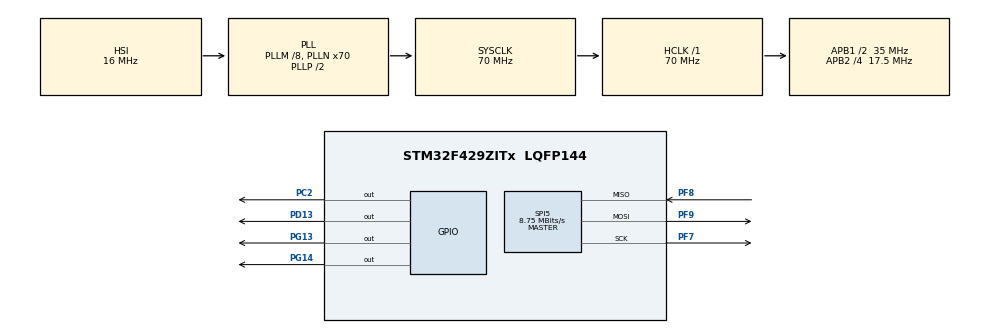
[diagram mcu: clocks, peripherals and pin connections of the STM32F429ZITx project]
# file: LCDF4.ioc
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Mcu.Family=STM32F4
Mcu.Name=STM32F429ZITx
Mcu.Package=LQFP144
NVIC.PriorityGroup=NVIC_PRIORITYGROUP_0
PC2.Signal=GPIO_Output
PD13.Signal=GPIO_Output
PF7.Mode=Full_Duplex_Master
PF7.Signal=SPI5_SCK
PF8.Mode=Full_Duplex_Master
PF8.Signal=SPI5_MISO
PF9.Mode=Full_Duplex_Master
PF9.Signal=SPI5_MOSI
PG13.Signal=GPIO_Output
PG14.Signal=GPIO_Output
PH0/OSC_IN.Mode=HSE-External-Oscillator
PH0/OSC_IN.Signal=RCC_OSC_IN
PH1/OSC_OUT.Mode=HSE-External-Oscillator
PH1/OSC_OUT.Signal=RCC_OSC_OUT
ProjectManager.HeapSize=0x200
ProjectManager.StackSize=0x400
ProjectManager.TargetToolchain=MDK-ARM V5
RCC.48MHZClocksFreq_Value=20000000
RCC.AHBFreq_Value=70000000
RCC.APB1CLKDivider=RCC_HCLK_DIV2
RCC.APB1Freq_Value=35000000
RCC.APB1TimFreq_Value=70000000
RCC.APB2CLKDivider=RCC_HCLK_DIV4
RCC.APB2Freq_Value=17500000
RCC.APB2TimFreq_Value=35000000
RCC.CortexFreq_Value=70000000
RCC.HCLKFreq_Value=70000000
RCC.HSE_VALUE=8000000
RCC.HSI_VALUE=16000000
RCC.LSE_VALUE=32768
RCC.PLLM=8
RCC.PLLN=70
RCC.PLLQ=7
RCC.SYSCLKFreq_VALUE=70000000
RCC.SYSCLKSource=RCC_SYSCLKSOURCE_PLLCLK
RCC.VCOOutputFreq_Value=140000000
SPI5.CalculateBaudRate=8.75 MBits/s
SPI5.Direction=SPI_DIRECTION_2LINES
SPI5.Mode=SPI_MODE_MASTER
SPI5.VirtualType=VM_MASTER
board=32F429IDISCOVERY

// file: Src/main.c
/* USER CODE BEGIN Header */
/**
  ******************************************************************************
  * @file           : main.c
  * @brief          : Main program body
  ******************************************************************************
  * @attention
  *
  * <h2><center>&copy; Copyright (c) 2020 STMicroelectronics.
  * All rights reserved.</center></h2>
  *
  * This software component is licensed by ST under BSD 3-Clause license,
  * the "License"; You may not use this file except in compliance with the
  * License. You may obtain a copy of the License at:
  *                        opensource.org/licenses/BSD-3-Clause
  *
  ******************************************************************************
  */
/* USER CODE END Header */

#include "main.h"
#include "spi.h"
#include "gpio.h"
#include "LCDLib.h"
#include "LCDGFX.h"
//#include "STM32.h"
#include "CNC.h"

void SystemClock_Config(void);

int main(void)
{

  /* MCU Configuration--------------------------------------------------------*/

  /* Reset of all peripherals, Initializes the Flash interface and the Systick. */
  HAL_Init();

  /* Configure the system clock */
  SystemClock_Config();

  /* Initialize all configured peripherals */
  MX_GPIO_Init();
  MX_SPI5_Init();
  /* USER CODE BEGIN 2 */
	ILI9341_Init();
	ILI9341_Fill_Screen(WHITE);
	//ILI9341_Draw_Text("STM32", 0, 0, BLACK, 3, WHITE);
	//HAL_Delay(2000);
  //ILI9341_printImage(0, 50, 80, 130, STM32, sizeof(STM32));
	//HAL_Delay(3000);
	ILI9341_Fill_Screen(WHITE);
	ILI9341_Draw_Text("CNC", 0, 0, BLACK, 3, WHITE);
	HAL_Delay(2000);
  ILI9341_printImage(0, 50, 122, 92, CNC, sizeof(CNC));

  /* USER CODE END 2 */

  /* Infinite loop */
  /* USER CODE BEGIN WHILE */
	uint16_t y = 0;
  while (1)
  {
    /* USER CODE END WHILE */

		//ILI9341_Draw_Rectangle(95, y, 50, 50, WHITE);
		//y = (y+5)%350;
		//ILI9341_Draw_Rectangle(95, y, 50, 50, BLUE);

		//HAL_Delay(100);
    /* USER CODE BEGIN 3 */
		HAL_GPIO_TogglePin(GPIOG, GPIO_PIN_13|GPIO_PIN_14);
		HAL_Delay(1000);
  }
  /* USER CODE END 3 */
}

void SystemClock_Config(void)
{
  RCC_OscInitTypeDef RCC_OscInitStruct = {0};
  RCC_ClkInitTypeDef RCC_ClkInitStruct = {0};

  /** Configure the main internal regulator output voltage
  */
  __HAL_RCC_PWR_CLK_ENABLE();
  __HAL_PWR_VOLTAGESCALING_CONFIG(PWR_REGULATOR_VOLTAGE_SCALE3);
  /** Initializes the CPU, AHB and APB busses clocks
  */
  RCC_OscInitStruct.OscillatorType = RCC_OSCILLATORTYPE_HSI;
  RCC_OscInitStruct.HSIState = RCC_HSI_ON;
  RCC_OscInitStruct.HSICalibrationValue = RCC_HSICALIBRATION_DEFAULT;
  RCC_OscInitStruct.PLL.PLLState = RCC_PLL_ON;
  RCC_OscInitStruct.PLL.PLLSource = RCC_PLLSOURCE_HSI;
  RCC_OscInitStruct.PLL.PLLM = 8;
  RCC_OscInitStruct.PLL.PLLN = 70;
  RCC_OscInitStruct.PLL.PLLP = RCC_PLLP_DIV2;
  RCC_OscInitStruct.PLL.PLLQ = 7;
  if (HAL_RCC_OscConfig(&RCC_OscInitStruct) != HAL_OK)
  {
    Error_Handler();
  }
  /** Initializes the CPU, AHB and APB busses clocks
  */
  RCC_ClkInitStruct.ClockType = RCC_CLOCKTYPE_HCLK|RCC_CLOCKTYPE_SYSCLK
                              |RCC_CLOCKTYPE_PCLK1|RCC_CLOCKTYPE_PCLK2;
  RCC_ClkInitStruct.SYSCLKSource = RCC_SYSCLKSOURCE_PLLCLK;
  RCC_ClkInitStruct.AHBCLKDivider = RCC_SYSCLK_DIV1;
  RCC_ClkInitStruct.APB1CLKDivider = RCC_HCLK_DIV2;
  RCC_ClkInitStruct.APB2CLKDivider = RCC_HCLK_DIV4;

  if (HAL_RCC_ClockConfig(&RCC_ClkInitStruct, FLASH_LATENCY_2) != HAL_OK)
  {
    Error_Handler();
  }
}

void Error_Handler(void)
{
}

/************************ (C) COPYRIGHT STMicroelectronics *****END OF FILE****/
